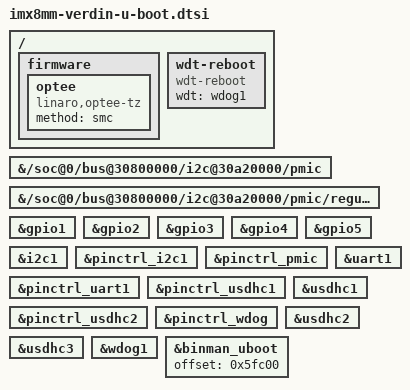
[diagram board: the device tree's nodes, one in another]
// SPDX-License-Identifier: GPL-2.0+ OR MIT
/*
 * Copyright 2020-2021 Toradex
 */

#include "imx8mm-u-boot.dtsi"

/ {
	firmware {
		optee {
			compatible = "linaro,optee-tz";
			method = "smc";
		};
	};

	wdt-reboot {
		compatible = "wdt-reboot";
		u-boot,dm-spl;
		wdt = <&wdog1>;
	};
};

&{/soc@0/bus@30800000/i2c@30a20000/pmic} {
	u-boot,dm-spl;
};

&{/soc@0/bus@30800000/i2c@30a20000/pmic/regulators} {
	u-boot,dm-spl;
};

&gpio1 {
	u-boot,dm-spl;
};

&gpio2 {
	u-boot,dm-spl;
};

&gpio3 {
	u-boot,dm-spl;
};

&gpio4 {
	u-boot,dm-spl;
};

&gpio5 {
	u-boot,dm-spl;
};

&i2c1 {
	u-boot,dm-spl;
};

&pinctrl_i2c1 {
	u-boot,dm-spl;
};

&pinctrl_pmic {
	u-boot,dm-spl;
};

&pinctrl_uart1 {
	u-boot,dm-spl;
};

&pinctrl_usdhc1 {
	u-boot,dm-spl;
};

&pinctrl_usdhc2 {
	u-boot,dm-spl;
};

&pinctrl_wdog {
	u-boot,dm-spl;
};

&uart1 {
	u-boot,dm-spl;
};

&usdhc1 {
	u-boot,dm-spl;
};

&usdhc2 {
	u-boot,dm-spl;
};

&usdhc3 {
	u-boot,dm-spl;
};

&wdog1 {
	u-boot,dm-spl;
};

&binman_uboot {
	offset = <0x5fc00>;
};
